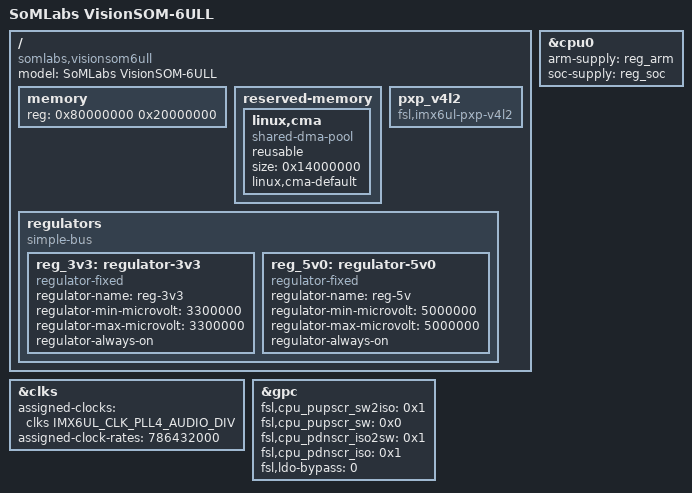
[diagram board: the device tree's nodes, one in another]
/*
 * This program is free software; you can redistribute it and/or modify
 * it under the terms of the GNU General Public License version 2 as
 * published by the Free Software Foundation.
 */

#include "imx6ull.dtsi"

/ {
    model = "SoMLabs VisionSOM-6ULL";
    compatible = "somlabs,visionsom6ull", "fsl,imx6ull";

    memory {
            reg = <0x80000000 0x20000000>;
    };

    reserved-memory {
            #address-cells = <1>;
            #size-cells = <1>;
            ranges;

            linux,cma {
	            compatible = "shared-dma-pool";
	            reusable;
	            size = <0x14000000>;
	            linux,cma-default;
            };
    };

    pxp_v4l2 {
            compatible = "fsl,imx6ul-pxp-v4l2", "fsl,imx6sx-pxp-v4l2", "fsl,imx6sl-pxp-v4l2";
            status = "okay";
    };

    /* Regulators */
    regulators {
        compatible = "simple-bus";
        #address-cells = <1>;
        #size-cells = <0>;
            
        /* 3.3V */
        reg_3v3: regulator-3v3 {
            compatible = "regulator-fixed";
            regulator-name = "reg-3v3";
            regulator-min-microvolt = <3300000>;
            regulator-max-microvolt = <3300000>;
            regulator-always-on;
        };

        /* 5V */
        reg_5v0: regulator-5v0 {
            compatible = "regulator-fixed";
            regulator-name = "reg-5v";
            regulator-min-microvolt = <5000000>;
            regulator-max-microvolt = <5000000>;
            regulator-always-on;
        };
    };
};

&cpu0 {
	arm-supply = <&reg_arm>;
	soc-supply = <&reg_soc>;
};

&clks {
	assigned-clocks = <&clks IMX6UL_CLK_PLL4_AUDIO_DIV>;
	assigned-clock-rates = <786432000>;
};

&gpc {
	fsl,cpu_pupscr_sw2iso = <0x1>;
	fsl,cpu_pupscr_sw = <0x0>;
	fsl,cpu_pdnscr_iso2sw = <0x1>;
	fsl,cpu_pdnscr_iso = <0x1>;
	fsl,ldo-bypass = <0>; /* DCDC, ldo-enable */
};


